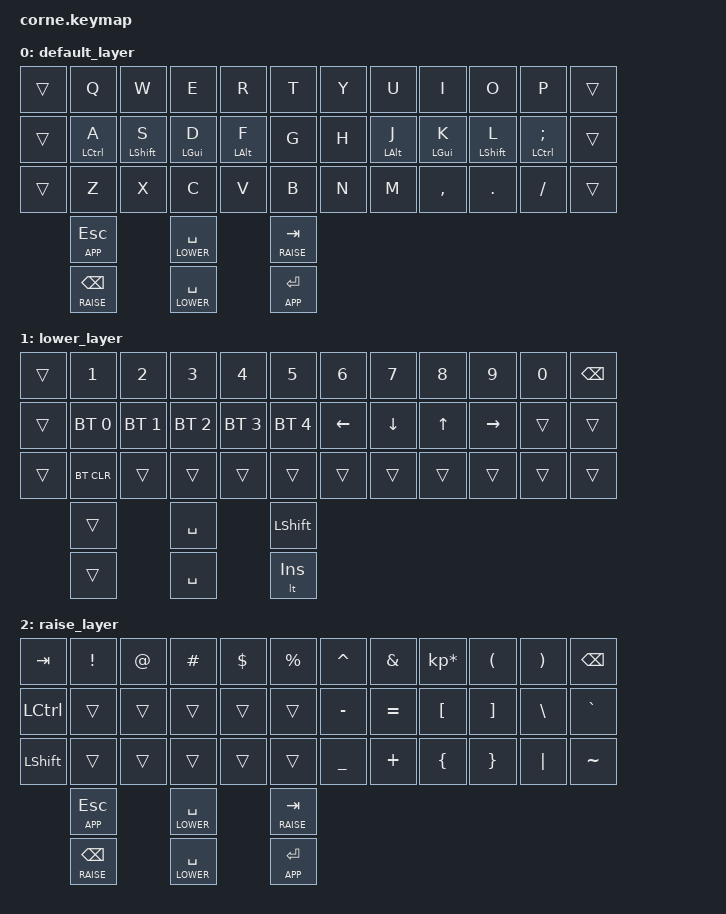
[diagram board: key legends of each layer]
/*
 * Copyright (c) 2020 The ZMK Contributors
 *
 * SPDX-License-Identifier: MIT
 */

#include <behaviors.dtsi>
#include <dt-bindings/zmk/keys.h>
#include <dt-bindings/zmk/bt.h>

#define L_DEFAULT 0
#define L_LOWER 1
#define L_RAISE 2
#define L_APP 3

/ {
keymap {
	compatible = "zmk,keymap";

default_layer {
// -----------------------------------------------------------------------------------------
// |  TAB |  Q  |  W  |  E  |  R  |  T  |   |  Y  |  U   |  I  |  O  |  P  | BKSP |
// | CTRL |  A  |  S  |  D  |  F  |  G  |   |  H  |  J   |  K  |  L  |  ;  |  '   |
// | SHFT |  Z  |  X  |  C  |  V  |  B  |   |  N  |  M   |  ,  |  .  |  /  | ESC  |
//                    | GUI | LWR | SPC |   | ENT | RSE  | ALT |
	bindings = <
&trans		&kp Q     &kp W     &kp E     &kp R     &kp T			&kp Y     &kp U     &kp I     &kp O     &kp P				&trans
&trans		&mt LCTRL A  &mt LSHIFT S  &mt LGUI D  &mt LALT F  &kp G	&kp H     &mt LALT J  &mt LGUI K  &mt LSHIFT L  &mt LCTRL SEMI		&trans
&trans		&kp Z     &kp X     &kp C     &kp V     &kp B			&kp N     &kp M     &kp COMMA &kp DOT   &kp FSLH			&trans
				&lt APP ESC		&lt LOWER SPACE		&lt RAISE TAB
				&lt RAISE BSPC		&lt LOWER SPACE		&lt APP RET
	>;
};

lower_layer {
// -----------------------------------------------------------------------------------------
// |  TAB |  1  |  2  |  3  |  4  |  5  |   |  6  |  7  |  8  |  9  |  0  | BKSP |
// | BTCLR| BT1 | BT2 | BT3 | BT4 | BT5 |   | LFT | DWN |  UP | RGT |     |      |
// | SHFT |     |     |     |     |     |   |     |     |     |     |     |      |
//                    | GUI |     | SPC |   | ENT |     | ALT |
	bindings = <
&trans		&kp N1    &kp N2    &kp N3    &kp N4    &kp N5			&kp N6    &kp N7    &kp N8    &kp N9    &kp N0				&kp BSPC
&trans		&bt BT_SEL 0 &bt BT_SEL 1 &bt BT_SEL 2 &bt BT_SEL 3 &bt BT_SEL 4	&kp LEFT    &kp DOWN  &kp UP    &kp RIGHT  &trans		&trans
&trans		&bt BT_CLR    &trans       &trans       &trans       &trans         &trans   &trans   &trans &trans    &trans &trans
				&trans			&kp SPACE		&kp LSHIFT
				&trans			&kp SPACE		&lt INS
				//&kp LGUI     &trans      	&kp SPACE     	&kp RET  &trans  	&kp RALT
	>;
};

raise_layer {
// -----------------------------------------------------------------------------------------
// |  TAB |  !  |  @  |  #  |  $  |  %  |   |  ^  |  &  |  *  |  (  |  )  | BKSP |
// | CTRL |     |     |     |     |     |   |  -  |  =  |  [  |  ]  |  \  |  `   |
// | SHFT |     |     |     |     |     |   |  _  |  +  |  {  |  }  | "|" |  ~   |
//                    | GUI |     | SPC |   | ENT |     | ALT |
                        bindings = <
	&kp  TAB 	&kp EXCL	&kp AT	&kp HASH	&kp DLLR	&kp PRCNT  	&kp CARET	&kp AMPS 	&kp KP_MULTIPLY	&kp LPAR	&kp RPAR	&kp BSPC
	&kp LCTRL &trans   &trans &trans   &trans   &trans     	&kp MINUS	&kp EQUAL	&kp LBKT       	&kp RBKT	&kp BSLH	&kp GRAVE
	&kp LSHFT &trans   &trans &trans   &trans   &trans     	&kp UNDER	&kp PLUS 	&kp LBRC       	&kp RBRC	&kp PIPE	&kp TILDE
				&lt APP ESC		&lt LOWER SPACE		&lt RAISE TAB
				&lt RAISE BSPC	&lt LOWER SPACE		&lt APP RET
					//&kp LGUI &trans  	&kp SPACE  	&kp RET   &trans   	&kp RALT
                        >;
                };
        };
};
